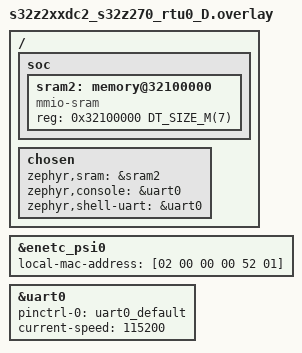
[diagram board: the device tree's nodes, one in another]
/*
 * SPDX-License-Identifier: Apache-2.0
 *
 * nros board overlay for s32z2xxdc2/s32z270/rtu0/D.
 *
 * The stock Zephyr board DTS at
 * `boards/nxp/s32z2xxdc2/s32z2xxdc2_s32z270_rtu0.dts` already wires
 * SRAM, the Cortex-R52 GIC, the LPUART console (uart0), the ENETC
 * PSI0 + MRU0 mailbox, and the watchdog. This overlay enables the
 * ENETC port for net stack and pins the chosen console / canbus.
 */

/ {
	soc {
		/* phase-292 W3.a (from the ASI deployment, hardware-validated):
		 * the RTU dts default sram is ~1 MiB — too small for a Cyclone
		 * image. The S32Z270 CRAM at 0x32100000 gives 7 MiB; move
		 * zephyr,sram there like the ASI zephyr-s32z platform does. */
		sram2: memory@32100000 {
			compatible = "mmio-sram";
			reg = <0x32100000 DT_SIZE_M(7)>;
		};
	};

	chosen {
		zephyr,sram = &sram2;
		zephyr,console = &uart0;
		zephyr,shell-uart = &uart0;
	};
};

&enetc_psi0 {
	status = "okay";
	local-mac-address = [02 00 00 00 52 01];
};

&uart0 {
	/* nxp,s32-linflexd marks pinctrl-0 required; the SoC dtsi leaves the
	 * node unpinned (the stock board dts only pins the uarts it enables). */
	pinctrl-0 = <&uart0_default>;
	pinctrl-names = "default";
	status = "okay";
	current-speed = <115200>;
};
